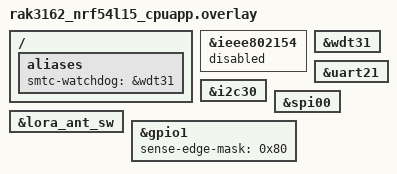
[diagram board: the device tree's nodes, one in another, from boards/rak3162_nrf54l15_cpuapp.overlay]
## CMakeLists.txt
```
# Copyright (c) 2026 RAKwireless Technology Limited
# SPDX-License-Identifier: Apache-2.0

cmake_minimum_required(VERSION 3.20.0)

# Pin rak-fw to this BSP revision (vendored at modules/rak-fw).
list(APPEND ZEPHYR_EXTRA_MODULES ${CMAKE_CURRENT_SOURCE_DIR}/../../modules/rak-fw)

# Optional unpublished factory extras as an external Zephyr module (not in this
# sample). Must be assigned before find_package(Zephyr).
#   -DRAK3162_AT_EXTRAS_DIR=/abs/path
#   or env RAK3162_AT_EXTRAS_DIR
#   or west-workspace sibling rak3162-at-factory/
# Use EXTRA_DTC_OVERLAY_FILE (append) rather than DTC_OVERLAY_FILE (would
# replace the board overlay discovered by Zephyr).
if(NOT RAK3162_AT_EXTRAS_DIR AND DEFINED ENV{RAK3162_AT_EXTRAS_DIR})
  set(RAK3162_AT_EXTRAS_DIR $ENV{RAK3162_AT_EXTRAS_DIR})
endif()
if(NOT RAK3162_AT_EXTRAS_DIR)
  get_filename_component(_west_ws ${CMAKE_CURRENT_SOURCE_DIR}/../../.. ABSOLUTE)
  if(EXISTS ${_west_ws}/rak3162-at-factory/zephyr/module.yml)
    set(RAK3162_AT_EXTRAS_DIR ${_west_ws}/rak3162-at-factory)
  endif()
endif()

if(RAK3162_AT_EXTRAS_DIR AND EXISTS ${RAK3162_AT_EXTRAS_DIR}/zephyr/module.yml)
  message(STATUS "at_firmware: factory extras module ${RAK3162_AT_EXTRAS_DIR}")
  list(APPEND ZEPHYR_EXTRA_MODULES ${RAK3162_AT_EXTRAS_DIR})
  if(EXISTS ${RAK3162_AT_EXTRAS_DIR}/factory.conf)
    set(EXTRA_CONF_FILE ${RAK3162_AT_EXTRAS_DIR}/factory.conf)
  endif()
  if(EXISTS ${RAK3162_AT_EXTRAS_DIR}/factory.overlay)
    set(EXTRA_DTC_OVERLAY_FILE ${RAK3162_AT_EXTRAS_DIR}/factory.overlay)
  endif()
endif()

find_package(Zephyr REQUIRED HINTS $ENV{ZEPHYR_BASE})

project(rak3162_at_firmware)

target_include_directories(app PRIVATE src)
target_sources(app PRIVATE src/main.c)
```

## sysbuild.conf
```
# Copyright (c) 2026 RAKwireless Technology Limited
# SPDX-License-Identifier: Apache-2.0
#
# Build MCUboot + application. First program still needs SWD (J-Link);
# later upgrades can use MCUboot serial recovery on uart20.

SB_CONFIG_BOOTLOADER_MCUBOOT=y
# Serial recovery writes the primary slot; dual-slot DTS kept for future app DFU.
SB_CONFIG_MCUBOOT_MODE_OVERWRITE_ONLY=y
```

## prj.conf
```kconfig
# Copyright (c) 2026 RAKwireless Technology Limited
# SPDX-License-Identifier: Apache-2.0

CONFIG_USE_SEGGER_RTT=n

# Power measurement: disable Zephyr LOG. AT +EVT still uses rak_at UART I/O.
CONFIG_LOG=n
CONFIG_BOOT_BANNER=n

CONFIG_SERIAL=y
CONFIG_CONSOLE=y
CONFIG_UART_CONSOLE=y
CONFIG_UART_ASYNC_API=y
# With PM_DEVICE=y this defaults off; enable so UARTE can gate clocks when RX is stopped.
CONFIG_UART_20_NRF_ASYNC_LOW_POWER=y

CONFIG_GPIO=y
CONFIG_HWINFO=y
CONFIG_NRF_GRTC_TIMER=y
CONFIG_CLOCK_CONTROL=y
CONFIG_CLOCK_CONTROL_NRF=y
CONFIG_REGULATOR=y
CONFIG_REGULATOR_FIXED=y
CONFIG_I2C=y
CONFIG_SPI=y

CONFIG_PM_DEVICE=y
CONFIG_TICKLESS_KERNEL=y
CONFIG_POWEROFF=y
CONFIG_REBOOT=y
CONFIG_WATCHDOG=n

CONFIG_MAIN_STACK_SIZE=4096
CONFIG_MAIN_THREAD_PRIORITY=-2
CONFIG_HEAP_MEM_POOL_SIZE=8192
# LoRaMAC TimerIrqHandler -> MacProcessNotify -> LoRaMacProcess runs here
CONFIG_SYSTEM_WORKQUEUE_STACK_SIZE=8192
# Drop debug instrumentation that adds idle overhead.
CONFIG_STACK_SENTINEL=n
CONFIG_THREAD_STACK_INFO=n
CONFIG_THREAD_MONITOR=n
CONFIG_THREAD_NAME=n
CONFIG_EXTRA_EXCEPTION_INFO=n
CONFIG_FAULT_DUMP=0

# Product firmware does not use Bluetooth.
CONFIG_BT=n

# RAK firmware framework (modules/rak-fw) + board runtime.
CONFIG_RAK_FW=y
CONFIG_RAK_FW_LORAWAN=y
CONFIG_RAK_FW_LORA_P2P=y
CONFIG_RAK_AT=y
CONFIG_RAK_AT_LORAWAN=y
CONFIG_RAK_AT_LORA_P2P=y
CONFIG_RAK_AT_UART_LP=y
# Sense wake (lower idle current). KEEP_RX≈155µA and avoids first-byte loss.
CONFIG_RAK_AT_UART_LP_KEEP_RX=n
CONFIG_RAK3162_RUNTIME=y

# Zephyr LoRa + LoRaWAN (loramac-node); default AT+BAND=4 (EU868).
# RAK3162 SX1262 is HF-only: no EU433 / CN470.
CONFIG_LORA=y
CONFIG_LORAWAN=y
CONFIG_LORAMAC_REGION_EU868=y
CONFIG_LORAMAC_REGION_RU864=y
CONFIG_LORAMAC_REGION_IN865=y
CONFIG_LORAMAC_REGION_US915=y
CONFIG_LORAMAC_REGION_AU915=y
CONFIG_LORAMAC_REGION_KR920=y
CONFIG_LORAMAC_REGION_AS923=y

CONFIG_ENTROPY_GENERATOR=y

CONFIG_PICOLIBC_USE_MODULE=n
CONFIG_NEWLIB_LIBC=y
CONFIG_NEWLIB_LIBC_NANO=y

CONFIG_FLASH=y
CONFIG_FLASH_MAP=y
CONFIG_NVS=y
CONFIG_SETTINGS=y
CONFIG_SETTINGS_NVS=y
```

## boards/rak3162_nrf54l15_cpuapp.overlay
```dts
/*
 * Copyright (c) 2026 RAKwireless Technology Limited
 * SPDX-License-Identifier: Apache-2.0
 */

/*
 * RAK3162 product firmware overlay
 */

/ {
	aliases {
		smtc-watchdog = &wdt31;
	};
};

&ieee802154 {
	status = "disabled";
};

&wdt31 {
	status = "okay";
};

/*
 * Secondary buses stay enabled in DT so drivers load, but the app suspends
 * them via pm_device between LoRaWAN windows (see bus_pm.c).
 */
&uart21 {
	status = "okay";
};

&i2c30 {
	status = "okay";
};

&spi00 {
	status = "okay";
};

/*
 * RF switch supply is enabled only around LoRaWAN Join/TX/RX windows
 * (see radio_bind board_rf_window_*), not left on from boot.
 */
&lora_ant_sw {
	/delete-property/ regulator-boot-on;
};

/*
 * P1.07 AT RX wake: use GPIO SENSE/DETECT (PORT) instead of a GPIOTE IN
 * channel. Edge+GPIOTE previously cost ~25 µA in System ON idle.
 */
&gpio1 {
	sense-edge-mask = <0x80>; /* BIT(7) = P1.07 */
};
```

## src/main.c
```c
/*
 * Copyright (c) 2026 RAKwireless Technology Limited
 * SPDX-License-Identifier: Apache-2.0
 *
 * Thin AT firmware sample: board bring-up + System ON idle / GRTC-timed uplink.
 * Framework join/send APIs live in rak-fw; OTAA defaults and sleep cycle live here.
 * Explicit AT+SLEEP still uses board System OFF (see radio_bind).
 */

#include <errno.h>
#include <stdlib.h>
#include <string.h>

#include <zephyr/drivers/hwinfo.h>
#include <zephyr/kernel.h>
#include <zephyr/logging/log.h>
#include <zephyr/sys/byteorder.h>
#include <zephyr/version.h>

#include "board/board_at_lp.h"
#include "core/bus_pm.h"
#include "core/led.h"
#include "radio/radio_bind.h"
#include "storage/storage.h"

#include <rak_at/rak_at.h>
#include <rak_at/rak_at_cfg.h>
#include <rak_at/rak_at_port.h>
#include <rak_at/rak_at_util.h>
#include <rak_fw/board.h>
#include <rak_fw/lora_p2p.h>
#include <rak_fw/lorawan.h>

LOG_MODULE_REGISTER(at_firmware, LOG_LEVEL_INF);

void app_extras_init(void);

/* Temporary test credentials; only seed fields missing from NVS. */
#define APP_OTAA_DEVEUI_HEX "0011223344556677"
#define APP_OTAA_APPEUI_HEX "0011223344556677"
#define APP_OTAA_APPKEY_HEX "00112233445566778899AABBCCDDEEFF"

#define APP_UPLINK_PORT 2U
#define APP_NVM_SETTLE_MS 100U
#define APP_MIN_SLEEP_MS 1000U
#define APP_JOIN_RETRY_MS 10000U

static struct k_work_delayable uplink_work;
static struct k_work_delayable join_retry_work;
static struct k_mutex cycle_lock;
static bool cycle_started;
static bool uplink_in_flight;
static bool sleep_requested;
static int64_t uplink_mark_ms;

static uint32_t app_send_interval_ms(void)
{
	return rak3162_storage_get_send_interval_s() * 1000U;
}

static bool app_auto_uplink_enabled(void)
{
	return !sleep_requested && (rak3162_storage_get_send_interval_s() != 0U);
}

static void cancel_auto_cycle_works_locked(void)
{
	(void)k_work_cancel_delayable(&uplink_work);
	(void)k_work_cancel_delayable(&join_retry_work);
}

static void stop_auto_uplink(void)
{
	struct k_work_sync sync;

	k_mutex_lock(&cycle_lock, K_FOREVER);
	cancel_auto_cycle_works_locked();
	k_mutex_unlock(&cycle_lock);

	/* Wait for a handler that already started; it must re-check before TX. */
	(void)k_work_cancel_delayable_sync(&uplink_work, &sync);

	k_mutex_lock(&cycle_lock, K_FOREVER);
	cancel_auto_cycle_works_locked();
	k_mutex_unlock(&cycle_lock);
}

static void log_reset_cause(void)
{
	uint32_t cause = 0U;
	int ret = hwinfo_get_reset_cause(&cause);

	if (ret == 0) {
		LOG_INF("Reset cause: 0x%08x", cause);
		(void)hwinfo_clear_reset_cause();
	}
}

static uint32_t compute_next_uplink_delay_ms(bool compensate_interval)
{
	uint32_t interval_ms = app_send_interval_ms();
	int64_t elapsed_ms;
	int64_t remain_ms;

	if (interval_ms == 0U) {
		return 0U;
	}

	if (!compensate_interval || (uplink_mark_ms <= 0)) {
		return interval_ms;
	}

	elapsed_ms = k_uptime_get() - uplink_mark_ms;
	if (elapsed_ms < 0) {
		elapsed_ms = 0;
	}

	/* System ON retains RAM, so there is no cold-boot budget to subtract. */
	remain_ms = (int64_t)interval_ms - elapsed_ms;
	if (remain_ms < (int64_t)APP_MIN_SLEEP_MS) {
		remain_ms = APP_MIN_SLEEP_MS;
	}

	return (uint32_t)remain_ms;
}

static void schedule_next_uplink(uint32_t minimum_idle_ms, bool compensate_interval)
{
	uint32_t delay_ms;

	k_mutex_lock(&cycle_lock, K_FOREVER);

	if (!app_auto_uplink_enabled()) {
		(void)k_work_cancel_delayable(&uplink_work);
		k_mutex_unlock(&cycle_lock);
		if (!sleep_requested) {
			LOG_INF("Auto uplink disabled (AT+SENDINT=0); use AT+SEND");
		}
		return;
	}

	delay_ms = compute_next_uplink_delay_ms(compensate_interval);
	if (delay_ms < minimum_idle_ms) {
		delay_ms = minimum_idle_ms;
	}

	/* Re-check immediately before arming GRTC so AT+SENDINT=0 cannot lose a race. */
	if (!app_auto_uplink_enabled()) {
		(void)k_work_cancel_delayable(&uplink_work);
		k_mutex_unlock(&cycle_lock);
		return;
	}

	/*
	 * Zephyr's tickless timeout is backed by the nRF GRTC. Returning from
	 * this handler lets the idle thread enter System ON WFI with RAM kept.
	 */
	LOG_INF("System ON idle %u ms (GRTC, target TX interval %u s)", delay_ms,
		rak3162_storage_get_send_interval_s());
	(void)k_work_reschedule(&uplink_work, K_MSEC(delay_ms));
	k_mutex_unlock(&cycle_lock);
}

static void schedule_uplink_now(void)
{
	k_mutex_lock(&cycle_lock, K_FOREVER);
	if (!app_auto_uplink_enabled()) {
		(void)k_work_cancel_delayable(&uplink_work);
		k_mutex_unlock(&cycle_lock);
		return;
	}
	(void)k_work_reschedule(&uplink_work, K_NO_WAIT);
	k_mutex_unlock(&cycle_lock);
}

static bool lorawan_mode_active(void)
{
	struct rak_at_runtime_cfg cfg;

	rak_at_cfg_get_active(&cfg);
	return cfg.nwm == RAK_AT_NWM_LORAWAN;
}

static void autojoin_on_boot(void);

static void join_retry_work_handler(struct k_work *work)
{
	ARG_UNUSED(work);
	LOG_INF("Retrying LoRaWAN autojoin");
	autojoin_on_boot();
}

static void schedule_join_retry(uint32_t delay_ms)
{
	k_mutex_lock(&cycle_lock, K_FOREVER);
	if (sleep_requested) {
		k_mutex_unlock(&cycle_lock);
		return;
	}

	LOG_INF("Join retry in %u ms (System ON/GRTC)", delay_ms);
	(void)k_work_reschedule(&join_retry_work, K_MSEC(delay_ms));
	k_mutex_unlock(&cycle_lock);
}

static void uplink_work_handler(struct k_work *work)
{
	uint8_t payload[4];
	uint32_t uplink_counter;
	int ret;

	ARG_UNUSED(work);

	if (!cycle_started || uplink_in_flight || !app_auto_uplink_enabled()) {
		return;
	}

	if (!lorawan_mode_active()) {
		return;
	}

	if (!rak_fw_lorawan_is_joined()) {
		schedule_join_retry(APP_JOIN_RETRY_MS);
		return;
	}

	if (!app_auto_uplink_enabled()) {
		return;
	}

	ret = rak_fw_lorawan_get_uplink_counter(&uplink_counter);
	if (ret != 0) {
		LOG_WRN("FCnt read failed: %d", ret);
		schedule_next_uplink(0U, false);
		return;
	}

	sys_put_be32(uplink_counter, payload);
	ret = rak_fw_lorawan_send_async(APP_UPLINK_PORT, payload, sizeof(payload),
					LORAWAN_MSG_UNCONFIRMED);
	if (ret == 0) {
		uplink_mark_ms = k_uptime_get();
		LOG_INF("Uplink queued (FCnt=%u)", uplink_counter);
		uplink_in_flight = true;
		return;
	}

	if (ret == -EBUSY) {
		k_mutex_lock(&cycle_lock, K_FOREVER);
		if (app_auto_uplink_enabled()) {
			(void)k_work_reschedule(&uplink_work, K_MSEC(100U));
		}
		k_mutex_unlock(&cycle_lock);
		return;
	}

	LOG_ERR("Uplink queue failed: %d", ret);
	schedule_next_uplink(0U, false);
}

static void on_send_done(int result)
{
	if (sleep_requested) {
		uplink_in_flight = false;
		return;
	}

	if (!uplink_in_flight) {
		return;
	}

	uplink_in_flight = false;
	radio_bind_prepare_system_on_idle();

	if (!app_auto_uplink_enabled()) {
		return;
	}

	if (result == 0) {
		schedule_next_uplink(APP_NVM_SETTLE_MS, true);
	} else {
		LOG_WRN("Uplink failed: %d; retry after full interval", result);
		schedule_next_uplink(0U, false);
	}
}

static void on_join_status(bool joined)
{
	if (sleep_requested) {
		uplink_in_flight = false;
		return;
	}

	if (joined) {
		(void)k_work_cancel_delayable(&join_retry_work);
		if (cycle_started) {
			uplink_in_flight = false;
			if (app_auto_uplink_enabled()) {
				schedule_uplink_now();
			} else {
				radio_bind_prepare_system_on_idle();
			}
			return;
		}
		cycle_started = true;
		uplink_in_flight = false;

		if (!app_auto_uplink_enabled()) {
			LOG_INF("LoRaWAN session ready; auto uplink off (AT+SENDINT=0)");
			radio_bind_prepare_system_on_idle();
			return;
		}

		LOG_INF("LoRaWAN session ready: send one Port%u uplink", APP_UPLINK_PORT);
		schedule_uplink_now();
		return;
	}

	LOG_WRN("Join unavailable; retry after full interval");
	radio_bind_prepare_system_on_idle();

	{
		struct rak_at_runtime_cfg cfg;

		rak_at_cfg_get_active(&cfg);
		if (cfg.nwm != RAK_AT_NWM_LORAWAN) {
			stop_auto_uplink();
			cycle_started = false;
			uplink_in_flight = false;
			(void)k_work_cancel_delayable(&join_retry_work);
			return;
		}
		if (cfg.join_auto == 0U) {
			(void)k_work_cancel_delayable(&join_retry_work);
			return;
		}
	}

	schedule_join_retry(APP_JOIN_RETRY_MS);
}

/** Called from AT+SLEEP prepare_poweroff: stop periodic TX before System OFF. */
static void app_prepare_sleep(void)
{
	sleep_requested = true;
	stop_auto_uplink();
	cycle_started = false;
	uplink_in_flight = false;
	(void)rak_fw_lorawan_join_stop();
	LOG_INF("Auto uplink/join cycle stopped for AT+SLEEP");
}

static int seed_test_otaa_creds_if_needed(struct rak_at_runtime_cfg *cfg)
{
	uint8_t value[RAK_AT_KEY_BIN_LEN];
	bool changed = false;
	int ret;

	if ((cfg->valid_mask & RAK_AT_CFG_VALID_DEVEUI) == 0U) {
		ret = rak_at_parse_hex_bytes(APP_OTAA_DEVEUI_HEX,
					     strlen(APP_OTAA_DEVEUI_HEX),
					     value, RAK_AT_EUI_BIN_LEN);
		if (ret != 0) {
			return ret;
		}
		memcpy(cfg->deveui, value, sizeof(cfg->deveui));
		cfg->valid_mask |= RAK_AT_CFG_VALID_DEVEUI;
		changed = true;
	}

	if ((cfg->valid_mask & RAK_AT_CFG_VALID_APPEUI) == 0U) {
		ret = rak_at_parse_hex_bytes(APP_OTAA_APPEUI_HEX,
					     strlen(APP_OTAA_APPEUI_HEX),
					     value, RAK_AT_EUI_BIN_LEN);
		if (ret != 0) {
			return ret;
		}
		memcpy(cfg->appeui, value, sizeof(cfg->appeui));
		cfg->valid_mask |= RAK_AT_CFG_VALID_APPEUI;
		changed = true;
	}

	if ((cfg->valid_mask & RAK_AT_CFG_VALID_APPKEY) == 0U) {
		ret = rak_at_parse_hex_bytes(APP_OTAA_APPKEY_HEX,
					     strlen(APP_OTAA_APPKEY_HEX),
					     value, RAK_AT_KEY_BIN_LEN);
		if (ret != 0) {
			return ret;
		}
		memcpy(cfg->appkey, value, sizeof(cfg->appkey));
		cfg->valid_mask |= RAK_AT_CFG_VALID_APPKEY;
		changed = true;
	}

	if (!changed) {
		return 0;
	}

	ret = rak_at_cfg_set_and_apply(cfg);
	if (ret != 0) {
		LOG_WRN("Failed to persist test OTAA credentials: %d", ret);
		return ret;
	}

	LOG_INF("Seeded missing test OTAA credentials");
	return 0;
}

static void autojoin_on_boot(void)
{
	struct rak_at_runtime_cfg cfg;
	const uint8_t *nwkkey;
	int ret;

	rak_at_cfg_get_active(&cfg);
	(void)seed_test_otaa_creds_if_needed(&cfg);
	rak_at_cfg_get_active(&cfg);

	if (cfg.nwm != RAK_AT_NWM_LORAWAN) {
		LOG_INF("Autojoin skipped: NWM=%u", cfg.nwm);
		return;
	}

	if (cfg.join_auto == 0U) {
		LOG_INF("Autojoin skipped: join_auto=0");
		return;
	}

	if (((cfg.valid_mask & RAK_AT_CFG_VALID_DEVEUI) == 0U) ||
	    ((cfg.valid_mask & RAK_AT_CFG_VALID_APPEUI) == 0U) ||
	    ((cfg.valid_mask & RAK_AT_CFG_VALID_APPKEY) == 0U)) {
		LOG_INF("Autojoin skipped: provision AT+DEVEUI/APPEUI/APPKEY first");
		return;
	}

	nwkkey = ((cfg.valid_mask & RAK_AT_CFG_VALID_NWKKEY) != 0U) ? cfg.nwkkey : cfg.appkey;
	ret = rak_fw_lorawan_ensure_started();
	if (ret != 0) {
		LOG_WRN("LoRaWAN start failed: %d", ret);
		schedule_join_retry(APP_JOIN_RETRY_MS);
		return;
	}

	if (rak_fw_lorawan_is_joined()) {
		LOG_INF("Autojoin skipped: already joined");
		return;
	}

	ret = rak_fw_lorawan_join_otaa_async(cfg.deveui, cfg.appeui, cfg.appkey, nwkkey,
					     cfg.join_interval_s, 1U);
	if (ret != 0) {
		LOG_WRN("Autojoin queue failed: %d", ret);
		schedule_join_retry(APP_JOIN_RETRY_MS);
		return;
	}

	LOG_INF("Autojoin queued");
}

static int cmd_sendint(const struct rak_at_request *req)
{
	unsigned long interval_ul;

	if (req->form == RAK_AT_FORM_HELP) {
		rak_at_resp_line(
			"AT+SENDINT: set/get auto uplink interval seconds (0=off, max %u)",
			RAK3162_SENDINT_MAX_S);
		rak_at_resp_ok();
		return 0;
	}

	if (req->form == RAK_AT_FORM_GET) {
		rak_at_resp_line("AT+SENDINT=%u", rak3162_storage_get_send_interval_s());
		rak_at_resp_ok();
		return 0;
	}

	if (req->form != RAK_AT_FORM_SET) {
		rak_at_resp_line("AT_PARAM_ERROR");
		return -EINVAL;
	}

	if ((rak_at_parse_ulong(req->args, &interval_ul) != 0) ||
	    (interval_ul > RAK3162_SENDINT_MAX_S)) {
		rak_at_resp_line("AT_PARAM_ERROR");
		return -EINVAL;
	}

	if (rak3162_storage_set_send_interval_s((uint32_t)interval_ul) != 0) {
		rak_at_resp_error(NULL);
		return -EIO;
	}

	if (interval_ul == 0U) {
		stop_auto_uplink();
		if (cycle_started && !uplink_in_flight) {
			radio_bind_prepare_system_on_idle();
		}
		LOG_INF("AT+SENDINT=0: auto uplink stopped");
	} else if (cycle_started && rak_fw_lorawan_is_joined() && !uplink_in_flight) {
		schedule_next_uplink(0U, false);
	}

	rak_at_resp_ok();
	return 0;
}

void app_policy_pause(void)
{
	stop_auto_uplink();
	(void)rak_fw_lorawan_join_stop();
}

void app_policy_resume(void)
{
	if (cycle_started && rak_fw_lorawan_is_joined() && app_auto_uplink_enabled() &&
	    !uplink_in_flight) {
		schedule_next_uplink(0U, false);
	} else if (cycle_started && !uplink_in_flight) {
		radio_bind_prepare_system_on_idle();
	}
}

__attribute__((weak)) void app_extras_init(void)
{
}

static void app_policy_start(void)
{
	k_mutex_init(&cycle_lock);
	k_work_init_delayable(&uplink_work, uplink_work_handler);
	k_work_init_delayable(&join_retry_work, join_retry_work_handler);
	rak_fw_lorawan_set_join_status_cb(on_join_status);
	rak_fw_lorawan_set_send_done_cb(on_send_done);
	radio_bind_set_pre_sleep_cb(app_prepare_sleep);
	(void)rak_at_register_command("SENDINT", cmd_sendint, "AT+SENDINT");
	autojoin_on_boot();
}

int main(void)
{
	int ret;

	ret = rak_at_port_init();
	if (ret != 0) {
		LOG_ERR("AT port init failed: %d", ret);
		return ret;
	}

	ret = board_at_lp_init();
	if (ret != 0) {
		LOG_ERR("Board AT LP init failed: %d", ret);
		return ret;
	}
	LOG_INF("AT port init done");
	log_reset_cause();

	ret = rak3162_storage_init();
	if (ret != 0) {
		LOG_ERR("Storage init failed: %d", ret);
	} else {
		LOG_INF("Storage init done");
	}
	rak3162_storage_bind_at_cfg();

	rak_fw_lora_p2p_init();
	rak_fw_lorawan_init();
	radio_bind_at();

	rak_at_init();
	rak_at_register_standard_commands();
	app_extras_init();
	LOG_INF("AT framework init done");

	/* Start with secondary buses suspended; resume only around RF windows. */
	rak3162_bus_pm_suspend();

	ret = rak3162_led_start();
	if (ret != 0) {
		LOG_ERR("LED init failed: %d", ret);
	}

	ret = rak_at_start();
	if (ret != 0) {
		LOG_ERR("AT runtime start failed: %d", ret);
		return ret;
	}

	/* Boot banner before autojoin so RF-window UART LP cannot drop it. */
	k_msleep(50);
	rak_at_resp_line("RAK3162 AT firmware ready");
	rak_at_print_command_list();
	rak_at_resp_ok();

	app_policy_start();

	LOG_INF("zephyr_version: %s", KERNEL_VERSION_STRING);
	LOG_INF("AT firmware ready (SENDINT=%u s, System ON idle)",
		rak3162_storage_get_send_interval_s());

	k_sleep(K_FOREVER);

	return 0;
}
```
